# R7FA8M1AH register map
Vendor: Renesas; Series: RA8; File version: 1.2
CPU: CM85 r0p0, little endian, MPU, FPU, VTOR, 4 interrupt priority bits
Registers are 32-bit, read-write, reset 0x0 unless marked. A register's access mark holds for its fields unless they carry their own. Offsets are from the block's base; [hi:lo] are bit positions; {n}, {i} and the like mark numbered series; 'fields as' and 'values as' point back to an identical list; <NAME> marks a mode.

## SYSC (part 2 of 2) — System Control
Base 0x4001E000
Same registers: SYSC_NS 0x5001E000
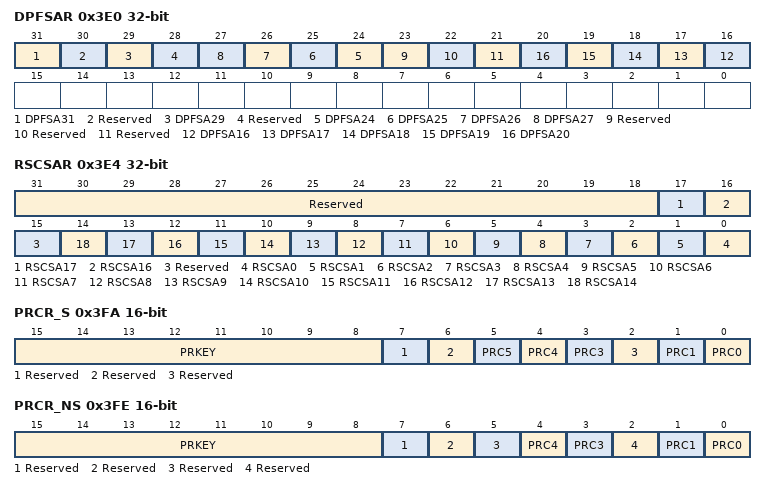
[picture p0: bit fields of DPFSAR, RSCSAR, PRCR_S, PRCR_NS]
0x3E0 DPFSAR — Deep Standby Interrupt Factor Security Attribution Register
  [31] DPFSA31 — Deep Standby Interrupt Factor Security Attribute bit 31
    0=Secure; 1=Non-secure
  [30] Reserved — This bit is read as 0. The write value should be 0.
  [29] DPFSA29 — Deep Standby Interrupt Factor Security Attribute bit 29
    0=Secure; 1=Non-secure
  [28] Reserved — This bit is read as 0. The write value should be 0.
  [n] DPFSA{n} (n=24..27) — Deep Standby Interrupt Factor Security Attribute bit {n}
    0=Secure; 1=Non-secure
  [23] Reserved — This bit is read as 0. The write value should be 0.
  [22] Reserved — This bit is read as 0. The write value should be 0.
  [21] Reserved — This bit is read as 0. The write value should be 0.
  [n] DPFSA{n} (n=16..20) — Deep Standby Interrupt Factor Security Attribute bit {n}
    0=Secure; 1=Non-secure
0x3E4 RSCSAR — RAM Standby Control Security Attribution Register
  [31:18] Reserved — These bits are read as 00000000000000. The write value should be 00000000000000.
  [17] RSCSA17 — RAM Standby Control Security Attribute bit 17
    0=Secure; 1=Non-secure
  [16] RSCSA16 — RAM Standby Control Security Attribute bit 16
    0=Secure; 1=Non-secure
  [15] Reserved — This bit is read as 0. The write value should be 0.
  [n] RSCSA{n} (n=0..14) — RAM Standby Control Security Attribute bit {n:02}
    0=Secure; 1=Non-secure
0x3FA PRCR_S 16-bit — Protect Register for Secure Register
  [15:8] PRKEY wo — PRC Key Code
    165=Enables writing to the PRCR_S register; other=others (Disables writing to the PRCR_S register.)
  [7] Reserved — This bit is read as 0. The write value should be 0.
  [6] Reserved — This bit is read as 0. The write value should be 0.
  [5] PRC5 — Enables writing to the registers related the reset control.
    0=Write disabled; 1=Write enabled
  [4] PRC4 — Enables writing to the registers related to the security and privilege setting registers.
    0=Write disabled; 1=Write enabled
  [3] PRC3 — Enables writing to the registers related to the PVD.
    0=Write disabled; 1=Write enabled
  [2] Reserved — This bit is read as 0. The write value should be 0.
  [1] PRC1 — Enables writing to the registers related to the operating modes, the low power modes, and the battery backup function.
    0=Write disabled; 1=Write enabled
  [0] PRC0 — Enables writing to the registers related to the clock generation circuit.
    0=Write disabled; 1=Write enabled
0x3FE PRCR_NS 16-bit — Protect Register for Non-secure Register
  [15:8] PRKEY wo — PRC Key Code
    165=Enables writing to the PRCR_NS register; other=others (Disables writing to the PRCR_NS register.)
  [7] Reserved — This bit is read as 0. The write value should be 0.
  [6] Reserved — This bit is read as 0. The write value should be 0.
  [5] Reserved — This bit is read as 0. The write value should be 0.
  [4] PRC4 — Enables writing to the registers related to the privilege setting registers.
    0=Write disabled; 1=Write enabled
  [3] PRC3 — Enables writing to the registers related to the PVD.
    0=Write disabled; 1=Write enabled
  [2] Reserved — This bit is read as 0. The write value should be 0.
  [1] PRC1 — Enables writing to the registers related to the operating modes, the low power modes, and the battery backup function.
    0=Write disabled; 1=Write enabled
  [0] PRC0 — Enables writing to the registers related to the clock generation circuit.
    0=Write disabled; 1=Write enabled
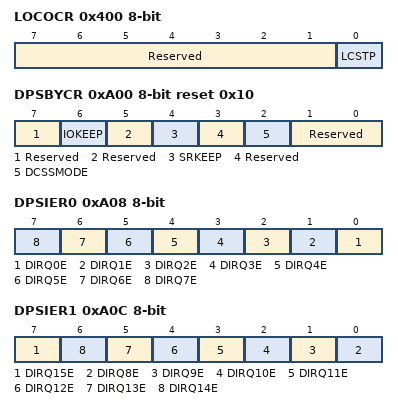
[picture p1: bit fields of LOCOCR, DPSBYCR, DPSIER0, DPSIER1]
0x400 LOCOCR 8-bit — Low-Speed On-Chip Oscillator Control Register
  [7:1] Reserved — These bits are read as 0000000. The write value should be 0000000.
  [0] LCSTP — LOCO Stop
    0=Operate the LOCO clock; 1=Stop the LOCO clock
0x402 LOCOUTCR 8-bit — LOCO User Trimming Control Register
  [7:0] LOCOUTRM — LOCO User Trimming
    128=-128; 129=-127; 130=-126; 255=-1; 0=Center Code; 1=+1; 125=+125; 126=+126; 127=+127
0xA00 DPSBYCR 8-bit reset 0x10 — Deep Standby Control Register
  [7] Reserved — This bit is read as 0. The write value should be 0.
  [6] IOKEEP — I/O Port Retention
    0=When the Deep Software Standby mode is canceled, the I/O ports are in the reset state; 1=When the Deep Software Standby mode is canceled, the I/O ports are in the same state as in the Deep Software Standby mode
  [5] Reserved — This bit is read as 0. The write value should be 0.
  [4] SRKEEP — Standby RAM Retention
    0=When entering the Software Standby mode or the Deep Software Standby mode, the contents of Standby RAM are not kept; 1=When entering the Software Standby mode or the Deep Software Standby mode 1, the contents of Standby RAM are kept
  [3] Reserved — This bit is read as 0. The write value should be 0.
  [2] DCSSMODE — DCDC SSMODE
    0=When the Deep Software Standby mode is canceled, the time required to recover is the standard time; 1=When the Deep Software Standby mode is canceled, the time required to recover is shortened
  [1:0] Reserved — These bits are read as 00. The write value should be 00.
0xA04 DPSWCR 8-bit reset 0xB — Deep Standby Wait Control Register
  [7:0] WTSTS — Deep Software Wait Standby Time Setting Bit
    11=Wait cycle for fast recovery; 154=Wait cycle for slow recovery; other=others (: Setting prohibited)
0xA08 DPSIER0 8-bit — Deep Standby Interrupt Enable Register 0
  [all] fields
    0=Cancelling deep software standby mode is disabled; 1=Cancelling deep software standby mode is enabled
  [n] DIRQ{n}E (n=0..7) — IRQ{n}-DS Pin Enable
0xA0C DPSIER1 8-bit — Deep Standby Interrupt Enable Register 1
  [7] DIRQ15E — IRQ15-DS Pin Enable
    0=Cancelling Deep Software Standby mode is disabled; 1=Cancelling Deep Software Standby mode is enabled
  [n-8] DIRQ{n}E (n=8..14) — IRQ{n}-DS Pin Enable
    values as the fields of DPSIER0
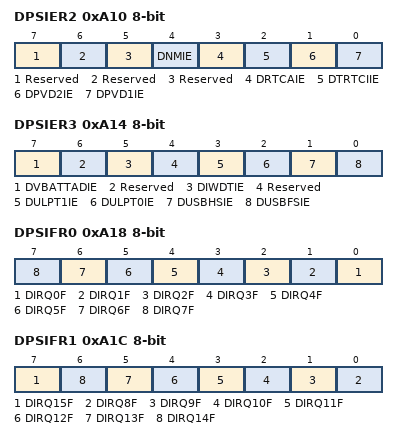
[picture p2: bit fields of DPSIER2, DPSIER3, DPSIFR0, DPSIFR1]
0xA10 DPSIER2 8-bit — Deep Standby Interrupt Enable Register 2
  [7] Reserved — This bit is read as 0. The write value should be 0.
  [6] Reserved — This bit is read as 0. The write value should be 0.
  [5] Reserved — This bit is read as 0. The write value should be 0.
  [4] DNMIE — NMI Pin Enable
    values as the fields of DPSIER0
  [3] DRTCAIE — RTC Alarm interrupt Deep Standby Cancel Signal Enable
    values as the fields of DPSIER0
  [2] DTRTCIIE — RTC Interval interrupt Deep Standby Cancel Signal Enable
    values as the fields of DPSIER0
  [1] DPVD2IE — PVD2 Deep Standby Cancel Signal Enable
    values as the fields of DPSIER0
  [0] DPVD1IE — PVD1 Deep Standby Cancel Signal Enable
    values as the fields of DPSIER0
0xA14 DPSIER3 8-bit — Deep Standby Interrupt Enable Register 3
  [7] DVBATTADIE — VBATT Tamper Detection Deep Standby Cancel Signal Enable
    values as DPSIER1.DIRQ15E
  [6] Reserved — This bit is read as 0. The write value should be 0.
  [5] DIWDTIE — IWDT Overflow Deep Standby Cancel Signal Enable
    values as DPSIER1.DIRQ15E
  [4] Reserved — This bit is read as 0. The write value should be 0.
  [3] DULPT1IE — ULPT1 Overflow Deep Standby Cancel Signal Enable
    values as the fields of DPSIER0
  [2] DULPT0IE — ULPT0 Overflow Deep Standby Cancel Signal Enable
    values as the fields of DPSIER0
  [1] DUSBHSIE — USBHS Suspend/Resume Deep Standby Cancel Signal Enable
    values as the fields of DPSIER0
  [0] DUSBFSIE — USBFS Suspend/Resume Deep Standby Cancel Signal Enable
    values as the fields of DPSIER0
0xA18 DPSIFR0 8-bit — Deep Standby Interrupt Flag Register 0
  [all] fields
    0=The cancel request is not generated; 1=The cancel request is generated
  [n] DIRQ{n}F (n=0..7) — IRQ{n}-DS Pin Deep Standby Cancel Flag
0xA1C DPSIFR1 8-bit — Deep Standby Interrupt Flag Register 1
  [all] fields
    values as the fields of DPSIFR0
  [7] DIRQ15F — IRQ15-DS Pin Deep Standby Cancel Flag
  [n-8] DIRQ{n}F write-0-clears read-modifies (n=8..14) — IRQ{n}-DS Pin Deep Standby Cancel Flag
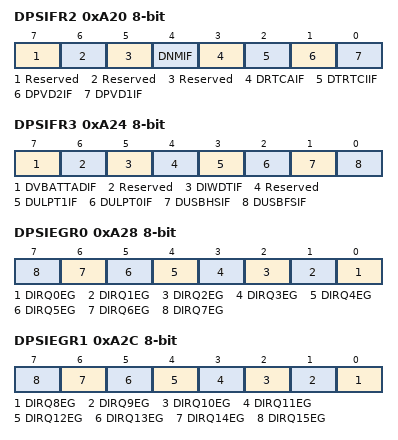
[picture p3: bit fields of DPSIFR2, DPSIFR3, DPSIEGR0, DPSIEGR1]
0xA20 DPSIFR2 8-bit — Deep Standby Interrupt Flag Register 2
  [7] Reserved — This bit is read as 0. The write value should be 0.
  [6] Reserved — This bit is read as 0. The write value should be 0.
  [5] Reserved — This bit is read as 0. The write value should be 0.
  [4] DNMIF write-0-clears read-modifies — NMI Pin Deep Standby Cancel Flag
    values as the fields of DPSIFR0
  [3] DRTCAIF write-0-clears read-modifies — RTC Alarm interrupt Deep Standby Cancel Flag
    values as the fields of DPSIFR0
  [2] DTRTCIIF write-0-clears read-modifies — RTC Interval interrupt Deep Standby Cancel Flag
    values as the fields of DPSIFR0
  [1] DPVD2IF write-0-clears read-modifies — PVD2 Deep Standby Cancel Flag
    values as the fields of DPSIFR0
  [0] DPVD1IF write-0-clears read-modifies — PVD1 Deep Standby Cancel Flag
    values as the fields of DPSIFR0
0xA24 DPSIFR3 8-bit — Deep Standby Interrupt Flag Register 3
  [7] DVBATTADIF write-0-clears read-modifies — VBATT Tamper Detection Deep Standby Cancel Flag
    values as the fields of DPSIFR0
  [6] Reserved — This bit is read as 0. The write value should be 0.
  [5] DIWDTIF write-0-clears read-modifies — IWDT Overflow Deep Standby Cancel Flag
    values as the fields of DPSIFR0
  [4] Reserved — This bit is read as 0. The write value should be 0.
  [3] DULPT1IF write-0-clears read-modifies — ULPT1 Overflow Deep Standby Cancel Flag
    values as the fields of DPSIFR0
  [2] DULPT0IF write-0-clears read-modifies — ULPT0 Overflow Deep Standby Cancel Flag
    values as the fields of DPSIFR0
  [1] DUSBHSIF write-0-clears read-modifies — USBHS Suspend/Resume Deep Standby Cancel Flag
    values as the fields of DPSIFR0
  [0] DUSBFSIF write-0-clears read-modifies — USBFS Suspend/Resume Deep Standby Cancel Flag
    values as the fields of DPSIFR0
0xA28 DPSIEGR0 8-bit — Deep Standby Interrupt Edge Register 0
  [all] fields
    0=A cancel request is generated at a falling edge; 1=A cancel request is generated at a rising edge
  [n] DIRQ{n}EG (n=0..7) — IRQ{n}-DS Pin Edge Select
0xA2C DPSIEGR1 8-bit — Deep Standby Interrupt Edge Register 1
  [all] fields
    values as the fields of DPSIEGR0
  [n-8] DIRQ{n}EG (n=8..15) — IRQ{n}-DS Pin Edge Select
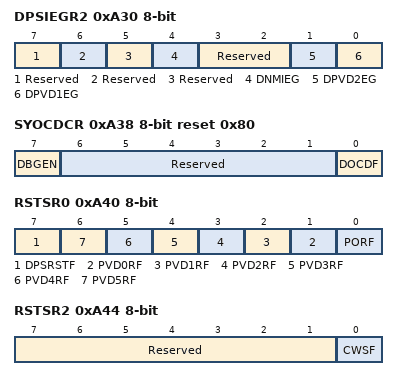
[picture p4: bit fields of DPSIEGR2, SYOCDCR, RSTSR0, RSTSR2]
0xA30 DPSIEGR2 8-bit — Deep Standby Interrupt Edge Register 2
  [7] Reserved — This bit is read as 0. The write value should be 0.
  [6] Reserved — This bit is read as 0. The write value should be 0.
  [5] Reserved — This bit is read as 0. The write value should be 0.
  [4] DNMIEG — NMI Pin Edge Select
    values as the fields of DPSIEGR0
  [3:2] Reserved — These bits are read as 00. The write value should be 00.
  [1] DPVD2EG — PVD2 Edge Select
    0=A cancel request is generated when VCC<Vdet2 (fall) is detected; 1=A cancel request is generated when VCC>=Vdet2 (rise) is detected
  [0] DPVD1EG — PVD1 Edge Select
    0=A cancel request is generated when VCC<Vdet1 (fall) is detected; 1=A cancel request is generated when VCC>=Vdet1 (rise) is detected
0xA38 SYOCDCR 8-bit reset 0x80 (reset mask 0xFE) — System Control OCD Control Register
  [7] DBGEN — Debugger Enable bit
    0=Disable on-chip debugger function; 1=Enable on-chip debugger function
  [6:1] Reserved — These bits are read as 000000. The write value should be 000000.
  [0] DOCDF write-0-clears read-modifies — Deep Standby OCD flag
    0=DBIRQ is not generated; 1=DBIRQ is generated
0xA40 RSTSR0 8-bit reset not defined — Reset Status Register 0
  [7] DPSRSTF write-0-clears read-modifies — Deep Software Standby Reset FlagNOTE: Writable only to clear the flag. Confirm the value is 1 and then write 0.
    0=Deep software standby mode cancelation not requested by an interrupt or a reset; 1=Deep software standby mode cancelation requested by an interrupt or a reset
  [n+1] PVD{n}RF write-0-clears read-modifies (n=0..5) — Voltage Monitor {n} Reset Detect FlagNOTE: Writable only to clear the flag. Confirm the value is 1 and then write 0.
    0=Voltage Monitor {n} reset not detected; 1=Voltage Monitor {n} reset detected
  [0] PORF write-0-clears read-modifies — Power-On Reset Detect FlagNOTE: Writable only to clear the flag. Confirm the value is 1 and then write 0.
    0=Power-on reset not detected; 1=Power-on reset detected
0xA44 RSTSR2 8-bit (reset mask 0xFE) — Reset Status Register 2
  [7:1] Reserved — These bits are read as 0000000. The write value should be 0000000.
  [0] CWSF write-1-sets read-modifies — Cold/Warm Start Determination Flag
    0=Cold start; 1=Warm start
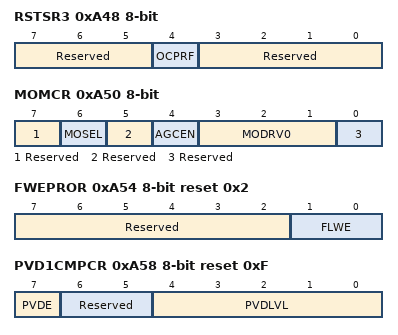
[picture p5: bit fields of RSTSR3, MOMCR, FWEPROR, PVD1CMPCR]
0xA48 RSTSR3 8-bit (reset mask 0xEE) — Reset Status Register 3
  [7:5] Reserved — These bits are read as 000. The write value should be 000.
  [4] OCPRF write-0-clears read-modifies — Overcurrent protection reset Detect Flag
    0=Overcurrent protection reset not detected; 1=Overcurrent protection reset detected
  [3:0] Reserved — These bits are read as 000. The write value should be 000.
0xA50 MOMCR 8-bit — Main Clock Oscillator Mode Oscillation Control Register
  [7] Reserved — This bit is read as 0. The write value should be 0.
  [6] MOSEL — Main Clock Oscillator Switching
    0=Resonator; 1=External clock input
  [5] Reserved — This bit is read as 0. The write value should be 0.
  [4] AGCEN — Auto Gain Control Enable
    0=Disable; 1=Enable
  [3:1] MODRV0 — Main Clock Oscillator Drive Capability 0 Switching
    0=8MHz; 1=8.1MHz to 16MHz; 2=16.1MHz to 20MHz; 3=20.1MHz to 26MHz; 4=48MHz; 5=48MHz (value after reset); 6=48MHz; 7=48MHz
  [0] Reserved — This bit is read as 0. The write value should be 0.
0xA54 FWEPROR 8-bit reset 0x2 — Flash Write Erase Protect Register
  [7:2] Reserved — These bits are read as 000000. The write value should be 000000.
  [1:0] FLWE — Flash Programing and Erasure
    0=Prohibits programming and erasure of the code flash, data flash or blank checking; 1=Permits programming and erasure of the code flash, data flash or blank checking; 2=Prohibits programming and erasure of the code flash, data flash or blank checking; 3=Prohibits programming and erasure of the code flash, data flash or blank checking
0xA58 PVD1CMPCR 8-bit reset 0xF — Voltage Monitor 1 Comparator Control Register
  [7] PVDE — Voltage Detection 1 Enable
    0=Voltage detection 1 circuit disabled; 1=Voltage detection 1 circuit enabled
  [6:5] Reserved — These bits are read as 00. The write value should be 00.
  [4:0] PVDLVL — Detection Voltage 1 Level Select(Standard voltage during drop in voltage)
    0=4.29V (Vdetm_0); 1=4.16V (Vdetm_1); 2=4.03V (Vdetm_2); 3=3.86V (Vdetm_3); 4=3.14V (Vdetm_4); 5=3.10V (Vdetm_5); 6=3.08V (Vdetm_6); 7=2.85V (Vdetm_7); 8=2.83V (Vdetm_8); 9=2.80V (Vdetm_9); 10=2.62V (Vdetm_10); 11=2.33V (Vdetm_11); 12=1.90V (Vdetm_12); 13=1.86V (Vdetm_13); 14=1.74V (Vdetm_14); 15=1.71V (Vdetm_15)
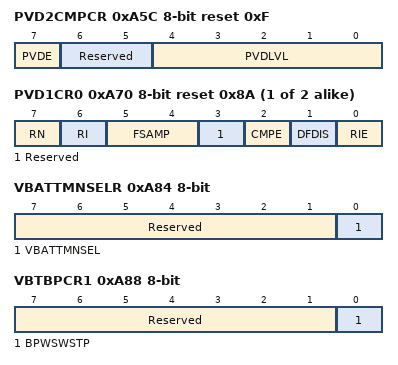
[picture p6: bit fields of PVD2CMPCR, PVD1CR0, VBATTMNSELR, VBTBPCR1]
0xA5C PVD2CMPCR 8-bit reset 0xF — Voltage Monitor 2 Comparator Control Register
  [7] PVDE — Voltage Detection 2 Enable
    0=Voltage detection 2 circuit disabled; 1=Voltage detection 2 circuit enabled
  [6:5] Reserved — These bits are read as 00. The write value should be 00.
  [4:0] PVDLVL — Detection Voltage 2 Level Select(Standard voltage during drop in voltage)
    values as PVD1CMPCR.PVDLVL
{0xA6C+4i} PVD{i}CR0 (i=1..2) 8-bit reset 0x8A (reset mask 0xF7) — Voltage Monitor {i} Circuit Control Register 0
  [7] RN — Voltage Monitor Reset Negate Select
    0=Negation follows a stabilization time (tPVD) after VCC > Vdet is detected; 1=Negation follows a stabilization time (tPVD) after assertion of the PVD reset
  [6] RI — Voltage Monitor Circuit Mode Select
    0=Voltage Monitor interrupt during Vdet1 passage; 1=Voltage Monitor reset enabled when the voltage falls to and below Vdet1
  [5:4] FSAMP — Sampling Clock Select
    0=1/2 LOCO frequency; 1=1/4 LOCO frequency; 2=1/8 LOCO frequency; 3=1/16 LOCO frequency
  [3] Reserved — This bit is read as 1. The write value should be 1.
  [2] CMPE — Voltage Monitor Circuit Comparison Result Output Enable
    0=Disable voltage monitor 1 circuit comparison result output; 1=Enable voltage monitor 1 circuit comparison result output
  [1] DFDIS — Voltage Monitor Digital Filter Disable Mode Select
    0=Enable digital filter; 1=Disable digital filter
  [0] RIE — Voltage Monitor Interrupt/Reset Enable
    0=Disable; 1=Enable
0xA84 VBATTMNSELR 8-bit — Battery Backup Voltage Monitor Function Select Register
  [7:1] Reserved — These bits are read as 0000000. The write value should be 0000000.
  [0] VBATTMNSEL — VBATT Voltage Monitor Function Select Bit
0xA88 VBTBPCR1 8-bit — VBATT Battery Power Supply Control Register 1
  [7:1] Reserved — These bits are read as 0000000. The write value should be 0000000.
  [0] BPWSWSTP — Battery Power Supply Switch Stop
    0=Battery power supply switch enable; 1=Battery power supply switch stop
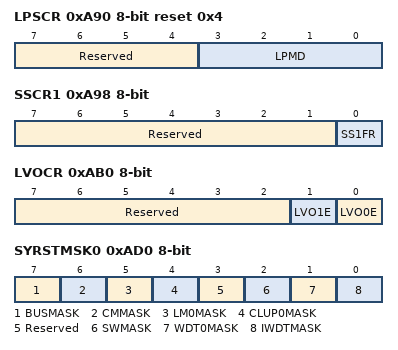
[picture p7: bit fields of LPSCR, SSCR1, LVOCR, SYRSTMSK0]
0xA90 LPSCR 8-bit reset 0x4 — Low Power State Control Register
  [7:4] Reserved — These bits are read as 0000. The write value should be 0000.
  [3:0] LPMD — Low power mode setting bit
    0=0h (System Active); 1=1h (Prohibited. (reserved)); 2=2h (Prohibited. (reserved) for CPU0 Deep Sleep); 3=3h (Prohibited. (reserved) CPU0 Power Gating); 4=4h (Software Standby mode 1); 5=5h (Software Standby mode 2); 6=6h (Prohibited. (reserved for Software Standby mode 3)); 7=7h (Prohibited. (reserved)); 8=8h (Deep Software Standby mode 1); 9=9h (Deep Software Standby mode 2); 10=Ah (Deep Software Standby mode 3)
0xA98 SSCR1 8-bit — Software Standby Control Register 1
  [7:1] Reserved — These bits are read as 0000000. The write value should be 0000000.
  [0] SS1FR — Software Standby 1 Fast Return
    0=When returning from Software Standby mode 1, fast return function is disabled; 1=When returning from Software Standby mode 1, fast return function is enabled
0xAB0 LVOCR 8-bit — Low Power State Control Register
  [7:2] Reserved — These bits are read as 000000. The write value should be 000000.
  [1] LVO1E — Low Voltage Operation 1 Enable
    0=Disable; 1=Enable
  [0] LVO0E — Low Voltage Operation 0 Enable
    0=Disable; 1=Enable
0xAD0 SYRSTMSK0 8-bit — System Reset Mask Control Register0
  [7] BUSMASK — BUS error Reset Mask
    0=Reset occurrence is enabled; 1=Reset occurrence is disabled
  [6] CMMASK — Common memory error Reset Mask
    values as BUSMASK
  [5] LM0MASK — Local memory 0 error Reset Mask
    values as BUSMASK
  [4] CLUP0MASK — CPU0 Lockup Reset Mask
    values as BUSMASK
  [3] Reserved — This bit is read as 0. The write value should be 0.
  [2] SWMASK — Software Reset Mask
    values as BUSMASK
  [1] WDT0MASK — CPU0 Watchdog timer Reset Mask
    values as BUSMASK
  [0] IWDTMASK — Independent watchdog timer Reset Mask
    values as BUSMASK
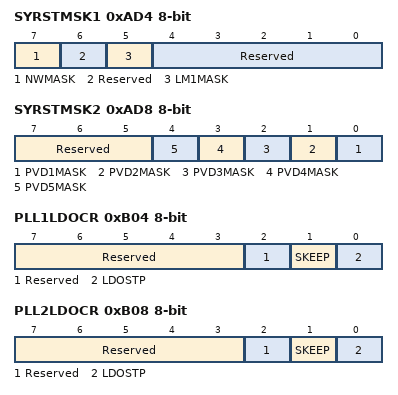
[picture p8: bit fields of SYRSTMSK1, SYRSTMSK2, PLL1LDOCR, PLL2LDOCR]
0xAD4 SYRSTMSK1 8-bit — System Reset Mask Control Register1
  [7] NWMASK — Network Reset Mask
    values as SYRSTMSK0.BUSMASK
  [6] Reserved — This bit is read as 0. The write value should be 0.
  [5] LM1MASK — Local memory 1 error Reset Mask
    values as SYRSTMSK0.BUSMASK
  [4:0] Reserved — These bits are read as 0. The write value should be 0.
0xAD8 SYRSTMSK2 8-bit — System Reset Mask Control Register2
  [7:5] Reserved — These bits are read as 000. The write value should be 000.
  [n-1] PVD{n}MASK (n=1..5) — Voltage Monitor {n} Reset Mask
    values as SYRSTMSK0.BUSMASK
0xB04 PLL1LDOCR 8-bit (reset mask 0xFB) — PLL1-LDO Control Register
  [7:3] Reserved — These bits are read as 00000. The write value should be 00000.
  [2] Reserved — This bit is read as 0. The write value should be 0.
  [1] SKEEP — STBY Keep
    0=PLL1-LDO is stopped during Software Standby mode; 1=PLL1-LDO state before Software Standby mode is retained during Software Standby mode
  [0] LDOSTP — LDO Stop
    0=PLL1-LDO is enabled; 1=PLL1-LDO is stopped
0xB08 PLL2LDOCR 8-bit (reset mask 0xFB) — PLL2-LDO Control Register
  [7:3] Reserved — These bits are read as 00000. The write value should be 00000.
  [2] Reserved — This bit is read as 0. The write value should be 0.
  [1] SKEEP — STBY Keep
    0=PLL2-LDO is stopped during Software Standby mode; 1=PLL2-LDO state before Software Standby mode is retained during Software Standby mode
  [0] LDOSTP — LDO Stop
    0=PLL2-LDO is enabled; 1=PLL2-LDO is stopped
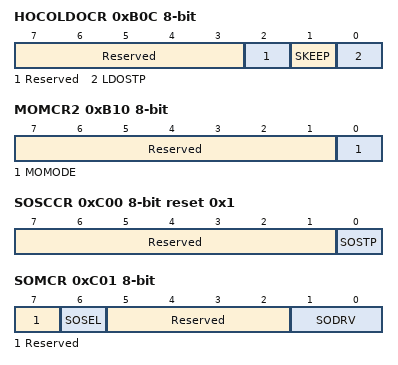
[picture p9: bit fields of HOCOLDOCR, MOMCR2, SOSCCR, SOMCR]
0xB0C HOCOLDOCR 8-bit — HOCO-LDO Control Register
  [7:3] Reserved — These bits are read as 00000. The write value should be 00000.
  [2] Reserved — This bit is read as 0. The write value should be 0.
  [1] SKEEP — STBY Keep
    0=HOCO-LDO is stopped during Software Standby mode; 1=HOCO-LDO state before Software Standby mode is retained during Software Standby mode
  [0] LDOSTP — LDO Stop
    0=HOCO-LDO is enabled; 1=HOCO-LDO is stopped
0xB10 MOMCR2 8-bit — Main Clock Oscillator Mode Control Register 2
  [7:1] Reserved — These bits are read as 0000000. The write value should be 0000000.
  [0] MOMODE — Main Clock Oscillator Mode Select
    0=Normal crystal oscillator mode (value after reset); 1=8M to 12MHz custom ceramic mode
0xC00 SOSCCR 8-bit reset 0x1 — Sub-clock oscillator control register
  [7:1] Reserved — These bits are read as 0000000. The write value should be 0000000.
  [0] SOSTP — Sub-Clock Oscillator Stop
    0=Operate the sub-clock oscillator; 1=Stop the sub-clock oscillator
0xC01 SOMCR 8-bit (reset mask 0xFD) — Sub Clock Oscillator Mode Control Register
  [7] Reserved — This bit is read as 0. The write value should be 0.
  [6] SOSEL — Sub Clock Oscillator Switching
    0=Resonator; 1=External clock input
  [5:2] Reserved — These bits are read as 0000. The write value should be 0000.
  [1:0] SODRV — Sub Clock Oscillator Drive Capability Switching
    0=:Standard(12.5pf) (value after reset); 1=Low power mode 1 (9pf); 2=Low power mode 2 (7pf); 3=Low power mode 3 (4pf)
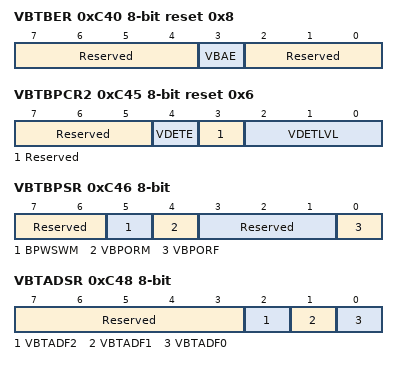
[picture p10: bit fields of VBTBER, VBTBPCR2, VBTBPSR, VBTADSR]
0xC40 VBTBER 8-bit reset 0x8 — VBATT Backup Enable Register
  [7:4] Reserved — These bits are read as 0000. The write value should be 0000.
  [3] VBAE — VBATT backup register access enable bit
    0=disable to access VBTBKR; 1=enable to access VBTBKR
  [2:0] Reserved — These bits are read as 000. The write value should be 000.
0xC45 VBTBPCR2 8-bit reset 0x6 — VBATT Battery Power Supply Control Register 2
  [7:5] Reserved — These bits are read as 000. The write value should be 000.
  [4] VDETE — Voltage drop detection enable
    0=VCC Voltage drop detection disable; 0b=Controlled by the power on reset of VCC; 1=VCC Voltage drop detection enable
  [3] Reserved — This bit is read as 0. The write value should be 0.
  [2:0] VDETLVL — VDETBAT Level Select
    0=2.8V; 1=2.53V; 2=2.10V; 3=1.95V; 4=1.85V; 5=1.75V; 6=1.65V; 7=prohibited (1.55V)
0xC46 VBTBPSR 8-bit — VBATT Battery Power Supply Status Register
  [7:6] Reserved — These bits are read as 00. The write value should be 00.
  [5] BPWSWM — Battery Power Supply Switch Status Monitor
    0=VCC voltage < VDETBAT; 1=VCC voltage > VDETBAT
  [4] VBPORM — VBATT_POR Monitor
    0=VBATT_R voltage < VVBATPOR; 1=VBATT_R voltage > VVBATPOR
  [3:1] Reserved — These bits are read as 000. The write value should be 000.
  [0] VBPORF — VBATT_POR Flag
    0=VBATT_R voltage drop is not detected; 1=VBATT_R voltage drop is detected
0xC48 VBTADSR 8-bit — VBATT Tamper detection Status Register
  [7:3] Reserved — These bits are read as 00000. The write value should be 00000.
  [2] VBTADF2 — VBATT Tamper Detection flag 2
    0=RTCIC2 input edge is not detected; 1=RTCIC2 input edge is detected
  [1] VBTADF1 — VBATT Tamper Detection flag 1
    0=RTCIC1 input edge is not detected; 1=RTCIC1 input edge is detected
  [0] VBTADF0 — VBATT Tamper Detection flag 0
    values as VBTADF2
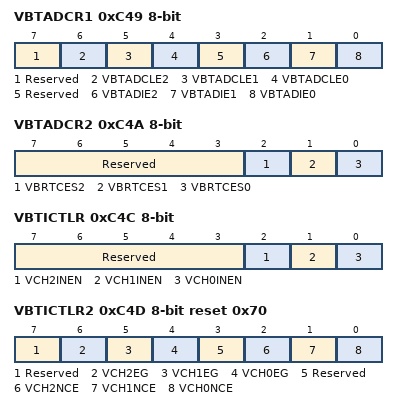
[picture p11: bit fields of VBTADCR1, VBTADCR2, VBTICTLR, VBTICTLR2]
0xC49 VBTADCR1 8-bit — VBATT Tamper detection Control Register 1
  [7] Reserved — This bit is read as 0. The write value should be 0.
  [6] VBTADCLE2 — VBATT Tamper Detection Backup Register Clear Enable 2
    0=Clear Backup Register by VBTADF2 flag is disable; 1=Clear Backup Register by VBTADF2 flag is enable
  [5] VBTADCLE1 — VBATT Tamper Detection Backup Register Clear Enable 1
    0=Clear Backup Register by VBTADF1 flag is disable; 1=Clear Backup Register by VBTADF1 flag is enable
  [4] VBTADCLE0 — VBATT Tamper Detection Backup Register Clear Enable 0
    0=Clear Backup Register by VBTADF0 flag is disable; 1=Clear Backup Register by VBTADF0 flag is enable
  [3] Reserved — This bit is read as 0. The write value should be 0.
  [2] VBTADIE2 — VBATT Tamper Detection Interrupt Enable 2
    0=Interrupt by VBTADF2 flag is disable; 1=Interrupt by VBTADF2 flag is enable
  [1] VBTADIE1 — VBATT Tamper Detection Interrupt Enable 1
    0=Interrupt by VBTADF1 flag is disable; 1=Interrupt by VBTADF1 flag is enable
  [0] VBTADIE0 — VBATT Tamper Detection Interrupt Enable 0
    0=Interrupt by VBTADF0 flag is disable; 1=Interrupt by VBTADF0 flag is enable
0xC4A VBTADCR2 8-bit — VBATT Tamper detection Control Register 2
  [7:3] Reserved — These bits are read as 00000. The write value should be 00000.
  [2] VBRTCES2 — VBATT RTC Time Capture Event Source Select 2
    0=RTCIC2; 1=VBTADF2
  [1] VBRTCES1 — VBATT RTC Time Capture Event Source Select 1
    0=RTCIC1; 1=VBTADF1
  [0] VBRTCES0 — VBATT RTC Time Capture Event Source Select 0
    0=RTCIC0; 1=VBTADF0
0xC4C VBTICTLR 8-bit — VBATT Input Control Register
  [7:3] Reserved — These bits are read as 00000. The write value should be 00000.
  [2] VCH2INEN — RTCIC2 Input Enable
    0=Disabled; 1=Enabled
  [1] VCH1INEN — RTCIC1 Input Enable
    0=Disabled; 1=Enabled
  [0] VCH0INEN — RTCIC0 Input Enable
    0=Disabled; 1=Enabled
0xC4D VBTICTLR2 8-bit reset 0x70 — VBATT Input Control Register 2
  [7] Reserved — This bit is read as 0. The write value should be 0.
  [6] VCH2EG — VBATT CH2 Input Edge Select
    0=RTCIC2 pin input event is detected on falling edge; 1=RTCIC2 pin input event is detected on rising edge
  [5] VCH1EG — VBATT CH1 Input Edge Select
    0=RTCIC1 pin input event is detected on falling edge; 1=RTCIC1 pin input event is detected on rising edge
  [4] VCH0EG — VBATT CH0 Input Edge Select
    0=RTCIC0 pin input event is detected on falling edge; 1=RTCIC0 pin input event is detected on rising edge
  [3] Reserved — This bit is read as 0. The write value should be 0.
  [2] VCH2NCE — VBATT CH2 Input Noise Canceler Enable
    0=RTCIC2 pin input noise canceler disable; 1=RTCIC2 pin input noise canceler enable
  [1] VCH1NCE — VBATT CH1 Input Noise Canceler Enable
    0=RTCIC1 pin inputs noise canceler disable; 1=RTCIC1 pin input noise canceler enable
  [0] VCH0NCE — VBATT CH0 Input Noise Canceler Enable
    0=RTCIC0 pin input noise canceler disable; 1=RTCIC0 pin input noise canceler enable
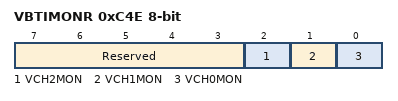
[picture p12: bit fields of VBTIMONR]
0xC4E VBTIMONR 8-bit (reset mask 0xF8) — VBATT Input Monitor Register
  [7:3] Reserved — These bits are read as 00000. The write value should be 00000.
  [2] VCH2MON — VBATT CH2 Input monitor
    0=RTCIC2 pin input is low level; 1=RTCIC2 pin input is high level
  [1] VCH1MON — VBATT CH1 Input monitor
    0=RTCIC1 pin input is low level; 1=RTCIC1 pin input is high level
  [0] VCH0MON — VBATT CH0 Input monitor
    0=RTCIC0 pin input is low level; 1=RTCIC0 pin input is high level
{0xD00+i} VBTBKR{i} (i=0..127) 8-bit — VBATT Backup Register {i}
  [7:0] VBTBKR — VBTBKRn [7:0] (n=0 to 127)
